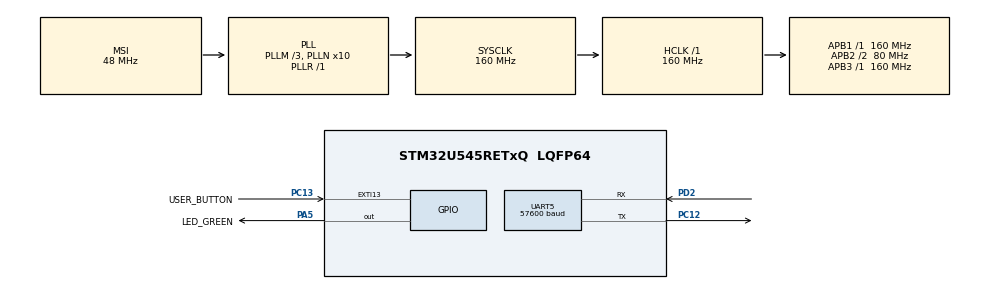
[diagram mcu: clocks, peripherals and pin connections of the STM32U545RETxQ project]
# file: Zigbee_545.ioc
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CORTEX_M33_NS.userName=CORTEX_M33
Mcu.Family=STM32U5
Mcu.Name=STM32U545RETxQ
Mcu.Package=LQFP64
NVIC.PriorityGroup=NVIC_PRIORITYGROUP_4
NVIC.UART5_IRQn=true\:0\:0\:false\:false\:true\:true\:true\:true
PA13\ (JTMS/SWDIO).Mode=Serial_Wire
PA13\ (JTMS/SWDIO).Signal=DEBUG_JTMS-SWDIO
PA14\ (JTCK/SWCLK).Mode=Serial_Wire
PA14\ (JTCK/SWCLK).Signal=DEBUG_JTCK-SWCLK
PA5.GPIO_Label=LED_GREEN
PA5.GPIO_PuPd=GPIO_PULLUP
PA5.GPIO_Speed=GPIO_SPEED_FREQ_HIGH
PA5.Signal=GPIO_Output
PC12.Mode=Asynchronous
PC12.Signal=UART5_TX
PC13.GPIO_Label=USER_BUTTON
PC13.GPIO_ModeDefaultEXTI=GPIO_MODE_IT_FALLING
PC13.GPIO_PuPd=GPIO_PULLDOWN
PC13.Signal=GPXTI13
PD2.Mode=Asynchronous
PD2.Signal=UART5_RX
PH0-OSC_IN\ (PH0).Mode=HSE-External-Oscillator
PH0-OSC_IN\ (PH0).Signal=RCC_OSC_IN
PH1-OSC_OUT\ (PH1).Mode=HSE-External-Oscillator
PH1-OSC_OUT\ (PH1).Signal=RCC_OSC_OUT
PWR.PowerMode=PWR_SMPS_SUPPLY
ProjectManager.HeapSize=0x200
ProjectManager.StackSize=0x400
ProjectManager.TargetToolchain=STM32CubeIDE
RCC.ADCFreq_Value=16000000
RCC.AHBFreq_Value=160000000
RCC.APB1Freq_Value=160000000
RCC.APB1TimFreq_Value=160000000
RCC.APB2CLKDivider=RCC_HCLK_DIV2
RCC.APB2Freq_Value=80000000
RCC.APB2TimFreq_Value=160000000
RCC.APB3Freq_Value=160000000
RCC.CortexFreq_Value=160000000
RCC.DACCLockSelectionVirtual=RCC_DAC1CLKSOURCE_LSI
RCC.DACCLockSelectionVirtualString=RCC_DAC1CLKSOURCE_LSI
RCC.EPOD_VALUE=48000000
RCC.HCLKFreq_Value=160000000
RCC.HSE_VALUE=8000000
RCC.HSI48_VALUE=48000000
RCC.HSI_VALUE=16000000
RCC.LSE_VALUE=32768
RCC.LSIDIV_VALUE=32000
RCC.MSIClockRange=RCC_MSIRANGE_0
RCC.MSI_VALUE=48000000
RCC.PLL1R=1
RCC.PLLFRACN=0
RCC.PLLM=3
RCC.PLLN=10
RCC.SYSCLKFreq_VALUE=160000000
RCC.SYSCLKSource=RCC_SYSCLKSOURCE_PLLCLK
RCC.USBFreq_Value=48000000
RCC.VCOOutputFreq_Value=160000000
UART5.BaudRate=57600
VP_ICACHE_VS_ICACHE.Mode=DirectMappedCache
VP_LPBAMQUEUE_VS_QUEUE.Mode=QUEUEMODE
VP_LPBAM_VS_SIG1.Mode=SmartRun
VP_LPBAM_VS_SIG4.Mode=LPDMA1
VP_MEMORYMAP_VS_MEMORYMAP.Mode=CurAppReg
VP_NUCLEO-U545RE-Q_VS_BSP_COMMON.Mode=COMMON
VP_PWR_VS_LPOM.Mode=PowerOptimisation
VP_PWR_VS_SECSignals.Mode=Security/Privilege
board=NUCLEO-U545RE-Q

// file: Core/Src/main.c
/* USER CODE BEGIN Header */
/**
  ******************************************************************************
  * @file           : main.c
  * @brief          : Main program body
  ******************************************************************************
  * @attention
  *
  * Copyright (c) 2024 STMicroelectronics.
  * All rights reserved.
  *
  * This software is licensed under terms that can be found in the LICENSE file
  * in the root directory of this software component.
  * If no LICENSE file comes with this software, it is provided AS-IS.
  *
  ******************************************************************************
  */
/* USER CODE END Header */
#include "main.h"

/* USER CODE BEGIN Includes */
#include <stdio.h>
#include <string.h>
/* USER CODE END Includes */

UART_HandleTypeDef huart5;

void SystemClock_Config(void);
static void SystemPower_Config(void);
static void MX_GPIO_Init(void);
static void MX_ICACHE_Init(void);
static void MX_UART5_Init(void);

/* USER CODE BEGIN 0 */
uint8_t counter = 0;
char sent_data[32] = " ";
uint8_t receiveData = 0;

/* USER CODE END 0 */

int main(void)
{

  /* MCU Configuration--------------------------------------------------------*/

  /* Reset of all peripherals, Initializes the Flash interface and the Systick. */
  HAL_Init();

  /* Configure the system clock */
  SystemClock_Config();

  /* Configure the System Power */
  SystemPower_Config();

  /* Initialize all configured peripherals */
  MX_GPIO_Init();
  MX_ICACHE_Init();
  MX_UART5_Init();

  /* Infinite loop */
  while (1)
  {

    /* USER CODE BEGIN 3 */

	  counter = counter + 1;
	  if (counter == 10){
		  counter = 0;
	  }

	  sprintf(sent_data, "Data: %d \n", counter);
	  HAL_UART_Transmit(&huart5, (uint8_t*) sent_data, strlen(sent_data), 100);

	  HAL_Delay(1000);

  }
  /* USER CODE END 3 */
}

void SystemClock_Config(void)
{
  RCC_OscInitTypeDef RCC_OscInitStruct = {0};
  RCC_ClkInitTypeDef RCC_ClkInitStruct = {0};

  /** Configure the main internal regulator output voltage
  */
  if (HAL_PWREx_ControlVoltageScaling(PWR_REGULATOR_VOLTAGE_SCALE1) != HAL_OK)
  {
    Error_Handler();
  }

  /** Initializes the CPU, AHB and APB buses clocks
  */
  RCC_OscInitStruct.OscillatorType = RCC_OSCILLATORTYPE_MSI;
  RCC_OscInitStruct.MSIState = RCC_MSI_ON;
  RCC_OscInitStruct.MSICalibrationValue = RCC_MSICALIBRATION_DEFAULT;
  RCC_OscInitStruct.MSIClockRange = RCC_MSIRANGE_0;
  RCC_OscInitStruct.PLL.PLLState = RCC_PLL_ON;
  RCC_OscInitStruct.PLL.PLLSource = RCC_PLLSOURCE_MSI;
  RCC_OscInitStruct.PLL.PLLMBOOST = RCC_PLLMBOOST_DIV4;
  RCC_OscInitStruct.PLL.PLLM = 3;
  RCC_OscInitStruct.PLL.PLLN = 10;
  RCC_OscInitStruct.PLL.PLLP = 2;
  RCC_OscInitStruct.PLL.PLLQ = 2;
  RCC_OscInitStruct.PLL.PLLR = 1;
  RCC_OscInitStruct.PLL.PLLRGE = RCC_PLLVCIRANGE_1;
  RCC_OscInitStruct.PLL.PLLFRACN = 0;
  if (HAL_RCC_OscConfig(&RCC_OscInitStruct) != HAL_OK)
  {
    Error_Handler();
  }

  /** Initializes the CPU, AHB and APB buses clocks
  */
  RCC_ClkInitStruct.ClockType = RCC_CLOCKTYPE_HCLK|RCC_CLOCKTYPE_SYSCLK
                              |RCC_CLOCKTYPE_PCLK1|RCC_CLOCKTYPE_PCLK2
                              |RCC_CLOCKTYPE_PCLK3;
  RCC_ClkInitStruct.SYSCLKSource = RCC_SYSCLKSOURCE_PLLCLK;
  RCC_ClkInitStruct.AHBCLKDivider = RCC_SYSCLK_DIV1;
  RCC_ClkInitStruct.APB1CLKDivider = RCC_HCLK_DIV1;
  RCC_ClkInitStruct.APB2CLKDivider = RCC_HCLK_DIV2;
  RCC_ClkInitStruct.APB3CLKDivider = RCC_HCLK_DIV1;

  if (HAL_RCC_ClockConfig(&RCC_ClkInitStruct, FLASH_LATENCY_4) != HAL_OK)
  {
    Error_Handler();
  }
}

/**
  * @brief Power Configuration
  * @retval None
  */
static void SystemPower_Config(void)
{

  /*
   * Switch to SMPS regulator instead of LDO
   */
  if (HAL_PWREx_ConfigSupply(PWR_SMPS_SUPPLY) != HAL_OK)
  {
    Error_Handler();
  }
}

static void MX_ICACHE_Init(void)
{

  /** Enable instruction cache in 1-way (direct mapped cache)
  */
  if (HAL_ICACHE_ConfigAssociativityMode(ICACHE_1WAY) != HAL_OK)
  {
    Error_Handler();
  }
  if (HAL_ICACHE_Enable() != HAL_OK)
  {
    Error_Handler();
  }

}

static void MX_UART5_Init(void)
{

  huart5.Instance = UART5;
  huart5.Init.BaudRate = 57600;
  huart5.Init.WordLength = UART_WORDLENGTH_8B;
  huart5.Init.StopBits = UART_STOPBITS_1;
  huart5.Init.Parity = UART_PARITY_NONE;
  huart5.Init.Mode = UART_MODE_TX_RX;
  huart5.Init.HwFlowCtl = UART_HWCONTROL_NONE;
  huart5.Init.OverSampling = UART_OVERSAMPLING_16;
  huart5.Init.OneBitSampling = UART_ONE_BIT_SAMPLE_DISABLE;
  huart5.Init.ClockPrescaler = UART_PRESCALER_DIV1;
  huart5.AdvancedInit.AdvFeatureInit = UART_ADVFEATURE_NO_INIT;
  if (HAL_UART_Init(&huart5) != HAL_OK)
  {
    Error_Handler();
  }
  if (HAL_UARTEx_SetTxFifoThreshold(&huart5, UART_TXFIFO_THRESHOLD_1_8) != HAL_OK)
  {
    Error_Handler();
  }
  if (HAL_UARTEx_SetRxFifoThreshold(&huart5, UART_RXFIFO_THRESHOLD_1_8) != HAL_OK)
  {
    Error_Handler();
  }
  if (HAL_UARTEx_DisableFifoMode(&huart5) != HAL_OK)
  {
    Error_Handler();
  }

}

static void MX_GPIO_Init(void)
{
  GPIO_InitTypeDef GPIO_InitStruct = {0};

  /* GPIO Ports Clock Enable */
  __HAL_RCC_GPIOC_CLK_ENABLE();
  __HAL_RCC_GPIOH_CLK_ENABLE();
  __HAL_RCC_GPIOA_CLK_ENABLE();
  __HAL_RCC_GPIOD_CLK_ENABLE();

  /*Configure GPIO pin Output Level */
  HAL_GPIO_WritePin(LED_GREEN_GPIO_Port, LED_GREEN_Pin, GPIO_PIN_RESET);

  /*Configure GPIO pin : USER_BUTTON_Pin */
  GPIO_InitStruct.Pin = USER_BUTTON_Pin;
  GPIO_InitStruct.Mode = GPIO_MODE_IT_FALLING;
  GPIO_InitStruct.Pull = GPIO_PULLDOWN;
  HAL_GPIO_Init(USER_BUTTON_GPIO_Port, &GPIO_InitStruct);

  /*Configure GPIO pin : LED_GREEN_Pin */
  GPIO_InitStruct.Pin = LED_GREEN_Pin;
  GPIO_InitStruct.Mode = GPIO_MODE_OUTPUT_PP;
  GPIO_InitStruct.Pull = GPIO_PULLUP;
  GPIO_InitStruct.Speed = GPIO_SPEED_FREQ_HIGH;
  HAL_GPIO_Init(LED_GREEN_GPIO_Port, &GPIO_InitStruct);

}

void Error_Handler(void)
{
  /* USER CODE BEGIN Error_Handler_Debug */
  /* User can add his own implementation to report the HAL error return state */
  __disable_irq();
  while (1)
  {
	  counter = counter + 1;
  }
  /* USER CODE END Error_Handler_Debug */
}
